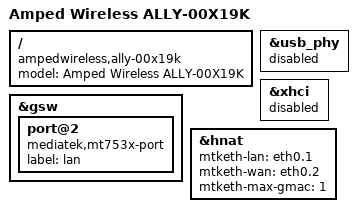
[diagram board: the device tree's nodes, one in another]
// SPDX-License-Identifier: GPL-2.0-or-later OR MIT

#include "mt7621_ampedwireless_ally.dtsi"

/ {
	compatible = "ampedwireless,ally-00x19k", "mediatek,mt7621-soc";
	model = "Amped Wireless ALLY-00X19K";
};

&gsw {

		port@2 {
		compatible = "mediatek,mt753x-port";
			status = "okay";
			label = "lan";
		};

};

&usb_phy {
	status = "disabled";
};

&xhci {
	status = "disabled";
};

&hnat {
	mtketh-lan = "eth0.1";
	mtketh-wan = "eth0.2";
	mtketh-max-gmac = <1>;
};
